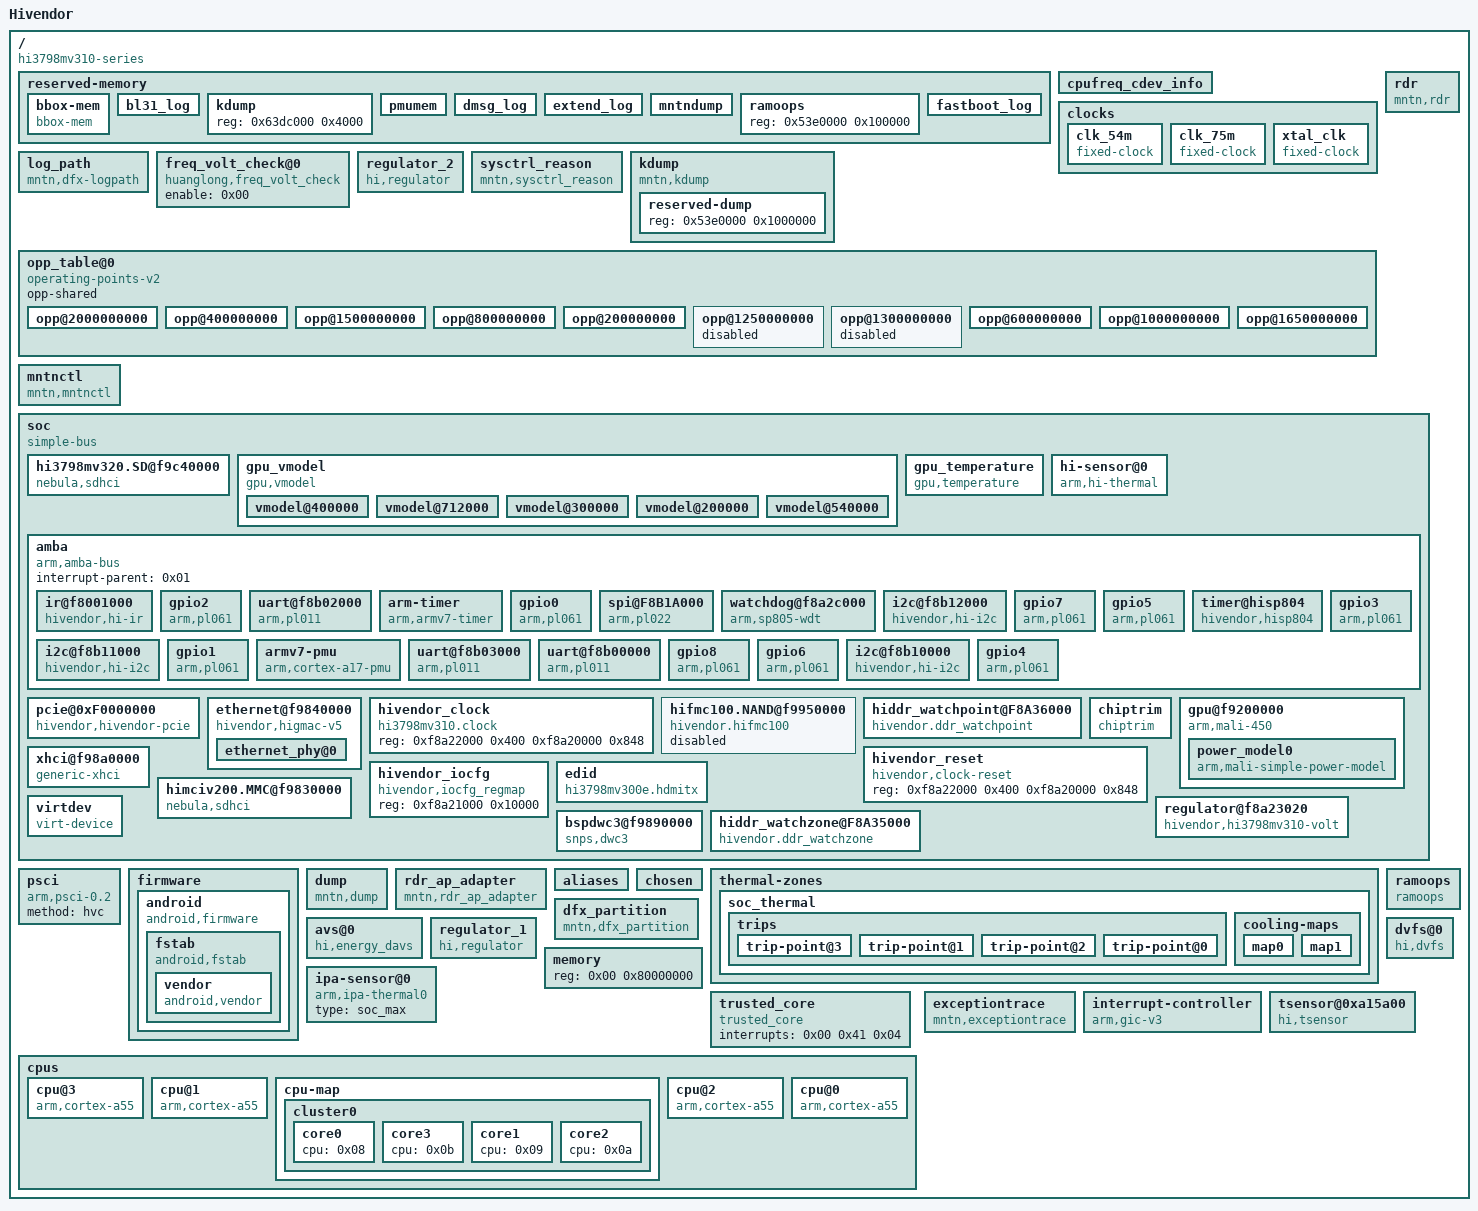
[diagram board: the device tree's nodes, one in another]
/dts-v1/;

/ {
	compatible = "hi3798mv310-series";
	model = "Hivendor";
	interrupt-parent = <0x01>;
	#address-cells = <0x01>;
	#size-cells = <0x01>;

	reserved-memory {
		ranges;
		#address-cells = <0x01>;
		#size-cells = <0x01>;
		phandle = <0x1f>;

		bbox-mem {
			compatible = "bbox-mem";
			no-map;
			phandle = <0x06>;
			reg = <0x5702000 0x4de000>;
		};

		bl31_log {
			no-map;
			reg = <0x5660000 0x80000>;
		};

		kdump {
			reg = <0x63dc000 0x4000>;
		};

		pmumem {
			no-map;
			reg = <0x5701000 0x1000>;
		};

		dmsg_log {
			no-map;
			reg = <0x54e0000 0x80000>;
		};

		extend_log {
			no-map;
			reg = <0x5560000 0x100000>;
		};

		mntndump {
			no-map;
			phandle = <0x07>;
			reg = <0x5700000 0x1000>;
		};

		ramoops {
			phandle = <0x20>;
			reg = <0x53e0000 0x100000>;
		};

		fastboot_log {
			no-map;
			reg = <0x56e0000 0x20000>;
		};
	};

	cpufreq_cdev_info {
		hi,cluster_num = <0x01>;
		hi,temperature_scale_capacitance = "-13169\03960\0-68\01\0605";
		hi,static_power_core_cap = "45\0-11969\01000";
		hi,hpm_param = <0xf80000b4 0x10 0xffff 0xe6 0x14a>;
		hi,ipa_cpufreq_table_index = <0x00>;
		hi,cluster_dyn_capacitance = <0x22f>;
		hi,cluster_static_capacitance = <0x8c>;
	};

	clocks {

		clk_54m {
			compatible = "fixed-clock";
			#clock-cells = <0x00>;
			phandle = <0x21>;
			clock-output-names = "clk54M";
			clock-frequency = <0x337f980>;
		};

		clk_75m {
			compatible = "fixed-clock";
			#clock-cells = <0x00>;
			phandle = <0x10>;
			clock-output-names = "clk75M";
			clock-frequency = <0x47868c0>;
		};

		xtal_clk {
			compatible = "fixed-clock";
			#clock-cells = <0x00>;
			phandle = <0x0f>;
			clock-output-names = "clk24M";
			clock-frequency = <0x16e3600>;
		};
	};

	log_path {
		compatible = "mntn,dfx-logpath";
		dfx_ready_path = "/data/lost+found";
		dfx_root_path = "/data/";
	};

	freq_volt_check@0 {
		compatible = "huanglong,freq_volt_check";
		enable = <0x00>;
		phandle = <0x1d>;
	};

	rdr {
		bbox_area_coreid = <0x01 0x02 0x04 0x08 0x10 0x20 0x40 0x80 0x100 0x200 0x400 0x800 0x1000 0x2000 0x4000 0x8000 0x10000>;
		rdr-dumpctl = "1111111111100000";
		compatible = "mntn,rdr";
		rdr-diaginfo-size = <0x20000>;
		bbox_area_names = "AP\0CP\0TEEOS\0HIFI\0BL31\0IOM3\0ISP\0IVP\0EMMC\0MODEMAP\0CLK\0REGULATOR\0BFM\0OUTSEE\0NPU\0CONN\0EXCEPTIONTRACE";
		rdr-log-max-nums = <0x0a>;
		rdr_area_sizes = <0x00 0x00 0x40000 0x40000 0x00 0x00 0x00 0x00 0x00 0x00 0x00 0x00 0x10000 0x00 0x00 0x2000 0x00>;
		rdr-log-max-size = <0x1f400000>;
		status = "ok";
		unexpected-max-reboot-times = <0x05>;
		bbox_addr = <0x06>;
		wait-dumplog-timeout = <0x1d4c0>;
		rdr_area_num = <0x11>;
	};

	regulator_2 {
		duty_step_value = <0x01>;
		compatible = "hi,regulator";
		pwm_addr = <0xf8a23018>;
		status = "okay";
		step_num = <0xdd>;
		phandle = <0x0e>;
		volt_reg_sleep_time = <0x00>;
		regulator-min-microvolt = <0xb90f0>;
		volt_reg_type = <0x00>;
		regulator-max-microvolt = <0x124f80>;
		regulator-always-on;
		volt_reg_step = <0x00>;
		max_v_duty = <0x00>;
		regulator-name = "cpu";
	};

	sysctrl_reason {
		compatible = "mntn,sysctrl_reason";
		sysctrl_reason_offset = <0x00 0x01 0x02 0x03 0x04 0x05 0x06 0x07 0x08 0x09 0x0a 0x0b 0x0c 0x0d 0x0e 0x0f 0x10 0x11 0x12 0x13 0x14 0x15 0x16 0x17>;
		sysctrl_reason_string = "AP_S_TSENSOR0\0AP_S_TSENSOR1\0G3D_S_G3DTSENSOR\0softreset\0AP_S_AWDT\0CHARGER_S_WDT\0LPM3_S_LPMCURST\0CP_S_CPTSENSOR\0IOM3_S_IOMCURST\0ASP_S_ASPWD\0CP_S_CPWD\0CP_S_CPWD\0IVP_S_IVPWD\0ISP_S_ISPWD\0AP_S_DDR_SELFREFLASH\0AP_S_DDR_FATAL_INTER\0AP_S_DDR_FATAL_INTER\0AP_S_DDR_FATAL_INTER\0AP_S_DDR_FATAL_INTER\0AP_S_DDR_UCE_WD\0AP_S_DDR_UCE_WD\0AP_S_DDR_UCE_WD\0AP_S_DDR_UCE_WD\0OCBC_S_WD";
	};

	kdump {
		compatible = "mntn,kdump";

		reserved-dump {
			#address-cells = <0x01>;
			#size-cells = <0x01>;
			reg = <0x53e0000 0x1000000>;
		};
	};

	opp_table@0 {
		compatible = "operating-points-v2";
		phandle = <0x0d>;
		opp-shared;

		opp@2000000000 {
			opp-microvolt = <0xf4240>;
			opp-hz = <0x00 0x77359400>;
			opp-microamp = <0xafc8>;
			clock-latency-ns = <0x493e0>;
		};

		opp@400000000 {
			opp-microvolt = <0xf4240>;
			opp-hz = <0x00 0x17d78400>;
			opp-microamp = <0x2710>;
			clock-latency-ns = <0x493e0>;
		};

		opp@1500000000 {
			opp-microvolt = <0xf4240>;
			opp-hz = <0x00 0x59682f00>;
			opp-microamp = <0xafc8>;
			clock-latency-ns = <0x493e0>;
		};

		opp@800000000 {
			opp-microvolt = <0xf4240>;
			opp-hz = <0x00 0x2faf0800>;
			opp-microamp = <0x2ee0>;
			clock-latency-ns = <0x493e0>;
		};

		opp@200000000 {
			opp-microvolt = <0xf4240>;
			opp-hz = <0x00 0xbebc200>;
			opp-microamp = <0x2710>;
			clock-latency-ns = <0x493e0>;
		};

		opp@1250000000 {
			opp-microvolt = <0xf4240>;
			opp-hz = <0x00 0x4a817c80>;
			opp-microamp = <0xafc8>;
			clock-latency-ns = <0x493e0>;
			status = "disabled";
		};

		opp@1300000000 {
			opp-microvolt = <0xf4240>;
			opp-hz = <0x00 0x4d7c6d00>;
			opp-microamp = <0xafc8>;
			clock-latency-ns = <0x493e0>;
			status = "disabled";
		};

		opp@600000000 {
			opp-microvolt = <0xf4240>;
			opp-hz = <0x00 0x23c34600>;
			opp-microamp = <0x2ee0>;
			clock-latency-ns = <0x493e0>;
		};

		opp@1000000000 {
			opp-microvolt = <0xf4240>;
			opp-hz = <0x00 0x3b9aca00>;
			opp-microamp = <0x2ee0>;
			clock-latency-ns = <0x493e0>;
		};

		opp@1650000000 {
			opp-microvolt = <0xf4240>;
			opp-hz = <0x00 0x62590080>;
			opp-microamp = <0xafc8>;
			clock-latency-ns = <0x493e0>;
		};
	};

	__symbols__ {
		tsensor = "/tsensor@0xa15a00";
		gpio2 = "/soc/amba/gpio2";
		gpu_vmodel = "/soc/gpu_vmodel";
		vddgpu = "/soc/regulator@f8a23020";
		bspdwc3 = "/soc/bspdwc3@f9890000";
		ir = "/soc/amba/ir@f8001000";
		gpio0 = "/soc/amba/gpio0";
		gpu_temperature = "/soc/gpu_temperature";
		gpu = "/soc/gpu@f9200000";
		regulator_2 = "/regulator_2";
		rsvmem = "/reserved-memory";
		clk_54m = "/clocks/clk_54m";
		cpu_opp_table = "/opp_table@0";
		gpio7 = "/soc/amba/gpio7";
		watchdog0 = "/soc/amba/watchdog@f8a2c000";
		hii2c2 = "/soc/amba/i2c@f8b12000";
		freq_volt_check = "/freq_volt_check@0";
		gic = "/interrupt-controller";
		gpio5 = "/soc/amba/gpio5";
		hivendor_clock = "/soc/hivendor_clock";
		threshold = "/thermal-zones/soc_thermal/trips/trip-point@0";
		uart2 = "/soc/amba/uart@f8b02000";
		hii2c0 = "/soc/amba/i2c@f8b10000";
		avs_compensation = "/avs@0";
		CPU2 = "/cpus/cpu@2";
		hiddr_watchzone = "/soc/hiddr_watchzone@F8A35000";
		emmc = "/soc/himciv200.MMC@f9830000";
		spi = "/soc/amba/spi@F8B1A000";
		gpio3 = "/soc/amba/gpio3";
		pcie = "/soc/pcie@0xF0000000";
		uart0 = "/soc/amba/uart@f8b00000";
		CPU0 = "/cpus/cpu@0";
		fmc = "/soc/hifmc100.NAND@f9950000";
		hdmitx = "/soc/edid";
		chiptrim = "/soc/chiptrim";
		gpio1 = "/soc/amba/gpio1";
		clk_75m = "/clocks/clk_75m";
		higmac0 = "/soc/ethernet@f9840000";
		critical = "/thermal-zones/soc_thermal/trips/trip-point@3";
		mntn_mem = "/reserved-memory/bbox-mem";
		xtal_clk = "/clocks/xtal_clk";
		hivendor_reset = "/soc/hivendor_reset";
		hivendor_iocfg = "/soc/hivendor_iocfg";
		cluster0 = "/cpus/cpu-map/cluster0";
		dvfs = "/dvfs@0";
		sdio = "/soc/hi3798mv320.SD@f9c40000";
		regulator_1 = "/regulator_1";
		power_model0 = "/soc/gpu@f9200000/power_model0";
		gpio8 = "/soc/amba/gpio8";
		hi_sensor0 = "/soc/hi-sensor@0";
		xhci_1 = "/soc/xhci@f98a0000";
		ramoops_ram = "/reserved-memory/ramoops";
		ipa_sensor0 = "/ipa-sensor@0";
		gpio6 = "/soc/amba/gpio6";
		dump_mem = "/reserved-memory/mntndump";
		uart3 = "/soc/amba/uart@f8b03000";
		hii2c1 = "/soc/amba/i2c@f8b11000";
		hiddr_watchpoint = "/soc/hiddr_watchpoint@F8A36000";
		CPU3 = "/cpus/cpu@3";
		gpio4 = "/soc/amba/gpio4";
		eth_phy0 = "/soc/ethernet@f9840000/ethernet_phy@0";
		target = "/thermal-zones/soc_thermal/trips/trip-point@1";
		hot = "/thermal-zones/soc_thermal/trips/trip-point@2";
		CPU1 = "/cpus/cpu@1";
	};

	mntnctl {
		compatible = "mntn,mntnctl";
		mntnctl = "010010111100101010111111101001100000011000001";
	};

	soc {
		compatible = "simple-bus";
		device_type = "soc";
		ranges = <0x00 0x00 0xffffffff>;
		#address-cells = <0x01>;
		#size-cells = <0x01>;

		hi3798mv320.SD@f9c40000 {
			sd-uhs-sdr25;
			compatible = "nebula,sdhci";
			clocks = <0x0c 0x2a4>;
			devid = <0x01>;
			cap-sd-highspeed;
			resets = <0x11 0x2a4 0x10 0x11 0x2a4 0x11 0x11 0x2a4 0x12 0x11 0x2a8 0x01>;
			clock-names = "mmc_clk";
			status = "okay";
			interrupts = <0x00 0x56 0x04>;
			bus-width = <0x04>;
			phandle = <0x37>;
			sd-uhs-sdr50;
			sd-uhs-sdr12;
			reg = <0xf9c40000 0x1000>;
			sd-uhs-sdr104;
			iocfg_regmap = <0x13>;
			reset-names = "crg_reset\0crg_tx\0crg_rx\0dll_reset";
			crg_regmap = <0x0c>;
			max-frequency = <0xb71b000>;
		};

		gpu_vmodel {
			compatible = "gpu,vmodel";
			phandle = <0x16>;

			vmodel@400000 {
				vmodel-hgain = <0x00>;
				vmodel-constant = <0x494>;
				vmodel-lgain = <0x32>;
				vmodel-minimum = <0x32a>;
				vmodel-ratio = <0x4c9>;
				vmodel-otp-volt = <0x28>;
			};

			vmodel@712000 {
				vmodel-hgain = <0x00>;
				vmodel-constant = <0x553>;
				vmodel-lgain = <0x1e>;
				vmodel-minimum = <0x32a>;
				vmodel-ratio = <0x677>;
				vmodel-otp-volt = <0x28>;
			};

			vmodel@300000 {
				vmodel-hgain = <0x00>;
				vmodel-constant = <0x479>;
				vmodel-lgain = <0x28>;
				vmodel-minimum = <0x32a>;
				vmodel-ratio = <0x480>;
				vmodel-otp-volt = <0x28>;
			};

			vmodel@200000 {
				vmodel-hgain = <0x00>;
				vmodel-constant = <0x479>;
				vmodel-lgain = <0x28>;
				vmodel-minimum = <0x32a>;
				vmodel-ratio = <0x480>;
				vmodel-otp-volt = <0x28>;
			};

			vmodel@540000 {
				vmodel-hgain = <0x00>;
				vmodel-constant = <0x494>;
				vmodel-lgain = <0x32>;
				vmodel-minimum = <0x32a>;
				vmodel-ratio = <0x4c9>;
				vmodel-otp-volt = <0x28>;
			};
		};

		gpu_temperature {
			h_temperature_h = <0x2d>;
			compatible = "gpu,temperature";
			phandle = <0x17>;
			l_temperature_l = <0x23>;
			h_temperature_l = <0x28>;
			l_temperature_h = <0x28>;
		};

		hi-sensor@0 {
			compatible = "arm,hi-thermal";
			#thermal-sensor-cells = <0x01>;
			phandle = <0x23>;
		};

		amba {
			compatible = "arm,amba-bus";
			ranges;
			interrupt-parent = <0x01>;
			#address-cells = <0x01>;
			#size-cells = <0x01>;

			ir@f8001000 {
				compatible = "hivendor,hi-ir";
				clocks = <0x0c 0x384>;
				interrupts = <0x00 0x2f 0x04>;
				phandle = <0x31>;
				reg = <0xf8001000 0x1000>;
				linux,rc-map-name = "rc-hi";
			};

			gpio2 {
				compatible = "arm,pl061\0arm,primecell";
				clocks = <0x0f>;
				clock-names = "apb_pclk";
				gpio-controller;
				#interrupt-cells = <0x02>;
				interrupts = <0x00 0x6e 0x04>;
				phandle = <0x26>;
				arm,primecell-periphid = <0x41061>;
				reg = <0xf8b22000 0x1000>;
				#gpio-cells = <0x02>;
				interrupt-controller;
			};

			uart@f8b02000 {
				compatible = "arm,pl011\0arm,primecell";
				clocks = <0x10>;
				clock-names = "apb_pclk";
				status = "okay";
				interrupts = <0x00 0x33 0x04>;
				phandle = <0x33>;
				arm,primecell-periphid = <0x241011>;
				reg = <0xf8b02000 0x1000>;
			};

			arm-timer {
				compatible = "arm,armv7-timer";
				interrupts = <0x01 0x0d 0xf04 0x01 0x0e 0xf04>;
				clock-frequency = <0x16e3600>;
			};

			gpio0 {
				compatible = "arm,pl061\0arm,primecell";
				clocks = <0x0f>;
				clock-names = "apb_pclk";
				gpio-controller;
				#interrupt-cells = <0x02>;
				interrupts = <0x00 0x6c 0x04>;
				phandle = <0x24>;
				arm,primecell-periphid = <0x41061>;
				reg = <0xf8b20000 0x1000>;
				#gpio-cells = <0x02>;
				interrupt-controller;
			};

			spi@F8B1A000 {
				compatible = "arm,pl022\0arm,primecell";
				clocks = <0x0c 0x70>;
				clock-names = "apb_pclk";
				#address-cells = <0x01>;
				interrupts = <0x00 0x2d 0x04>;
				#size-cells = <0x00>;
				phandle = <0x30>;
				arm,primecell-periphid = <0x41022>;
				reg = <0xf8b1a000 0x1000>;
				num-cs = <0x02>;
				pl022,rt;
			};

			watchdog@f8a2c000 {
				start_ping_in_kernel = <0x01>;
				compatible = "arm,sp805-wdt\0arm,primecell";
				clocks = <0x0f>;
				clock-names = "apb_pclk";
				interrupts = <0x00 0x1d 0x04>;
				phandle = <0x2c>;
				arm,primecell-periphid = <0x141805>;
				reg = <0xf8a2c000 0x1000>;
				timeout-sec = <0x0a>;
			};

			i2c@f8b12000 {
				compatible = "hivendor,hi-i2c";
				clocks = <0x0c 0x1b4>;
				clock-names = "apb_pclk";
				#address-cells = <0x01>;
				interrupts = <0x00 0x28 0x04>;
				#size-cells = <0x00>;
				phandle = <0x2f>;
				reg = <0xf8b12000 0x1000>;
				clock-frequency = <0x61a80>;
			};

			gpio7 {
				compatible = "arm,pl061\0arm,primecell";
				clocks = <0x0f>;
				clock-names = "apb_pclk";
				gpio-controller;
				#interrupt-cells = <0x02>;
				interrupts = <0x00 0x73 0x04>;
				phandle = <0x2a>;
				arm,primecell-periphid = <0x41061>;
				reg = <0xf8b27000 0x1000>;
				#gpio-cells = <0x02>;
				interrupt-controller;
			};

			gpio5 {
				compatible = "arm,pl061\0arm,primecell";
				clocks = <0x0f>;
				clock-names = "apb_pclk";
				gpio-controller;
				#interrupt-cells = <0x02>;
				interrupts = <0x00 0x71 0x00>;
				phandle = <0x28>;
				arm,primecell-periphid = <0x41061>;
				reg = <0xf8004000 0x1000>;
				#gpio-cells = <0x02>;
				interrupt-controller;
			};

			timer@hisp804 {
				compatible = "hivendor,hisp804";
				clocks = <0x0f>;
				clock-names = "apb_pclk";
				interrupts = <0x00 0x1a 0x04 0x00 0x3b 0x04 0x00 0x1b 0x04 0x00 0x3c 0x04>;
				reg = <0xf8a29000 0x20 0xf8a2a000 0x20 0xf8a2a020 0x20 0xf8a2b000 0x20 0xf8a2b020 0x20>;
			};

			gpio3 {
				compatible = "arm,pl061\0arm,primecell";
				clocks = <0x0f>;
				clock-names = "apb_pclk";
				gpio-controller;
				#interrupt-cells = <0x02>;
				interrupts = <0x00 0x6f 0x04>;
				phandle = <0x27>;
				arm,primecell-periphid = <0x41061>;
				reg = <0xf8b23000 0x1000>;
				#gpio-cells = <0x02>;
				interrupt-controller;
			};

			i2c@f8b11000 {
				compatible = "hivendor,hi-i2c";
				clocks = <0x0c 0x1b0>;
				clock-names = "apb_pclk";
				#address-cells = <0x01>;
				interrupts = <0x00 0x27 0x04>;
				#size-cells = <0x00>;
				phandle = <0x2e>;
				reg = <0xf8b11000 0x1000>;
				clock-frequency = <0x61a80>;
			};

			gpio1 {
				compatible = "arm,pl061\0arm,primecell";
				clocks = <0x0f>;
				clock-names = "apb_pclk";
				gpio-controller;
				#interrupt-cells = <0x02>;
				interrupts = <0x00 0x6d 0x04>;
				phandle = <0x25>;
				arm,primecell-periphid = <0x41061>;
				reg = <0xf8b21000 0x1000>;
				#gpio-cells = <0x02>;
				interrupt-controller;
			};

			armv7-pmu {
				compatible = "arm,cortex-a17-pmu";
				interrupts = <0x00 0x08 0x04 0x00 0x09 0x04 0x00 0x0a 0x04 0x00 0x0b 0x04>;
			};

			uart@f8b03000 {
				compatible = "arm,pl011\0arm,primecell";
				clocks = <0x10>;
				clock-names = "apb_pclk";
				status = "okay";
				interrupts = <0x00 0x34 0x04>;
				phandle = <0x34>;
				arm,primecell-periphid = <0x241011>;
				reg = <0xf8b03000 0x1000>;
			};

			uart@f8b00000 {
				compatible = "arm,pl011\0arm,primecell";
				clocks = <0x10>;
				clock-names = "apb_pclk";
				status = "okay";
				interrupts = <0x00 0x31 0x04>;
				phandle = <0x32>;
				arm,primecell-periphid = <0x241011>;
				reg = <0xf8b00000 0x1000>;
			};

			gpio8 {
				compatible = "arm,pl061\0arm,primecell";
				clocks = <0x0f>;
				clock-names = "apb_pclk";
				gpio-controller;
				#interrupt-cells = <0x02>;
				interrupts = <0x00 0x74 0x04>;
				phandle = <0x2b>;
				arm,primecell-periphid = <0x41061>;
				reg = <0xf8b28000 0x1000>;
				#gpio-cells = <0x02>;
				interrupt-controller;
			};

			gpio6 {
				compatible = "arm,pl061\0arm,primecell";
				clocks = <0x0f>;
				clock-names = "apb_pclk";
				gpio-controller;
				#interrupt-cells = <0x02>;
				interrupts = <0x00 0x72 0x04>;
				phandle = <0x29>;
				arm,primecell-periphid = <0x41061>;
				reg = <0xf8b26000 0x1000>;
				#gpio-cells = <0x02>;
				interrupt-controller;
			};

			i2c@f8b10000 {
				compatible = "hivendor,hi-i2c";
				clocks = <0x0c 0x1ac>;
				clock-names = "apb_pclk";
				#address-cells = <0x01>;
				interrupts = <0x00 0x26 0x04>;
				#size-cells = <0x00>;
				phandle = <0x2d>;
				reg = <0xf8b10000 0x1000>;
				clock-frequency = <0x61a80>;
			};

			gpio4 {
				compatible = "arm,pl061\0arm,primecell";
				clocks = <0x0f>;
				clock-names = "apb_pclk";
				gpio-controller;
				#interrupt-cells = <0x02>;
				interrupts = <0x00 0x70 0x04>;
				phandle = <0x14>;
				arm,primecell-periphid = <0x41061>;
				reg = <0xf8b24000 0x1000>;
				#gpio-cells = <0x02>;
				interrupt-controller;
			};
		};

		pcie@0xF0000000 {
			reset-gpio = <0x14 0x01 0x01>;
			compatible = "hivendor,hivendor-pcie\0snps,dw-pcie";
			clocks = <0x0c 0x3a0>;
			device_type = "pci";
			num-lanes = <0x01>;
			clock-names = "pcie_clk";
			ranges = <0x800 0x00 0xf2100000 0xf2100000 0x00 0x20000 0x81000000 0x00 0x00 0xf4000000 0x00 0x10000 0x82000000 0x00 0xf3000000 0xf3000000 0x00 0x1000000>;
			num-viewport = <0x03>;
			status = "okay";
			#address-cells = <0x03>;
			interrupts = <0x00 0x83 0x04 0x00 0x91 0x04 0x00 0x92 0x04 0x00 0x80 0x04>;
			#size-cells = <0x02>;
			phandle = <0x3b>;
			speed-limit = <0x02>;
			reg = <0xf0001000 0x200 0xf0000000 0x1000 0xf8c5f000 0x200>;
			#gpio-cells = <0x02>;
			interrupt-names = "intx\0protect-read-int\0protect-write-int\0msi";
		};

		ethernet@f9840000 {
			internal-phy;
			phy-handle = <0x12>;
			compatible = "hivendor,higmac-v5";
			mac-address = [14 2e 43 08 0f 15];
			clocks = <0x0c 0x3bc 0x0c 0xd0>;
			resets = <0x11 0x3bc 0x00 0x11 0xd0 0x00 0x11 0xcc 0x05>;
			phy-gpio-bit = <0x06>;
			clock-names = "higmac_clk\0macif_clk";
			phy-gpio-base = <0xf8b22000>;
			status = "okay";
			#address-cells = <0x01>;
			interrupts = <0x00 0x50 0x04 0x00 0x51 0x04 0x00 0x53 0x04 0x00 0x55 0x04>;
			#size-cells = <0x00>;
			phandle = <0x35>;
			reg = <0xf9840000 0x1000 0xf984300c 0x04>;
			phy-mode = "mii";
			reset-names = "port_reset\0macif_reset\0phy_reset";

			ethernet_phy@0 {
				phy_fixup_id = <0x1cc878>;
				phandle = <0x12>;
				reg = <0x03>;
				phy_fixup0 = <0x1f0d08 0x00 0x110100 0x02 0x1f0000 0x00>;
			};
		};

		hivendor_clock {
			compatible = "hi3798mv310.clock\0syscon";
			#clock-cells = <0x01>;
			phandle = <0x0c>;
			reg = <0xf8a22000 0x400 0xf8a20000 0x848>;
		};

		hifmc100.NAND@f9950000 {
			compatible = "hivendor.hifmc100";
			clocks = <0x0c 0x380>;
			clock-names = "clk";
			status = "disabled";
			interrupts = <0x00 0x36 0x04>;
			phandle = <0x38>;
			reg = <0xf9950000 0x100 0xfe200000 0x2176>;
		};

		hiddr_watchpoint@F8A36000 {
			compatible = "hivendor.ddr_watchpoint";
			interrupts = <0x00 0x1f 0x04>;
			phandle = <0x3c>;
			reg = <0xf8a36000 0x1000>;
		};

		chiptrim {
			compatible = "chiptrim";
			chiptrim2 = <0x21>;
			chiptrim0 = <0x21fb9420>;
			phandle = <0x22>;
			chiptrim1 = <0x34623>;
		};

		gpu@f9200000 {
			gpu_vmodel = <0x16>;
			cooling-min-state = <0x00>;
			pmu_domain_config = <0x01 0x02 0x02 0x00 0x00 0x00 0x00 0x00 0x00 0x01 0x02 0x00>;
			compatible = "arm,mali-450\0arm,mali-utgard";
			clocks = <0x0c 0x124>;
			gpu_temperature = <0x17>;
			operating-points-tt = <0xbebc200 0x30d40 0x11e1a300 0x493e0 0x17d78400 0x61a80 0x202fbf00 0x83d60 0x2a704200 0xadd40>;
			min-utilization = <0x1e>;
			default-frequency = <0x202fbf00>;
			clock-names = "clk_mali";
			ipa-model = "mali-simple-power-model";
			status = "okay";
			interrupt-parent = <0x01>;
			interrupts = <0x00 0x5e 0x04 0x00 0x5e 0x04 0x00 0x5e 0x04 0x00 0x5e 0x04 0x00 0x5e 0x04 0x00 0x5e 0x04 0x00 0x5e 0x04 0x00 0x5e 0x04>;
			irq_affinity = <0x03>;
			phandle = <0x05>;
			mali-supply = <0x15>;
			reg = <0xf9200000 0x10000>;
			cooling-max-state = <0x06>;
			max-utilization = <0x3c>;
			#cooling-cells = <0x02>;
			min-frequency = <0xbebc200>;
			interrupt-names = "IRQGP\0IRQGPMMU\0IRQPP0\0IRQPPMMU0\0IRQPP1\0IRQPPMMU1\0IRQPMU\0IRQPP";
			max-frequency = "*pB";
			pmu_switch_delay = <0x1ff>;

			power_model0 {
				dynamic-coefficient = <0x299>;
				compatible = "arm,mali-simple-power-model";
				static-coefficient = <0x9d05>;
				thermal-zone = [00];
				phandle = <0x40>;
				ts = <0xffffac8e 0xf01 0xffffffa6 0x01>;
			};
		};

		hivendor_reset {
			compatible = "hivendor,clock-reset\0syscon";
			#reset-cells = <0x02>;
			phandle = <0x11>;
			reg = <0xf8a22000 0x400 0xf8a20000 0x848>;
		};

		hivendor_iocfg {
			compatible = "hivendor,iocfg_regmap\0syscon";
			#reset-cells = <0x03>;
			phandle = <0x13>;
			reg = <0xf8a21000 0x10000>;
		};

		xhci@f98a0000 {
			compatible = "generic-xhci";
			clocks = <0x0c 0x2d0>;
			clock-names = "clk";
			status = "okay";
			interrupts = <0x00 0x40 0x04>;
			phandle = <0x3a>;
			reg = <0xf98a0000 0x10000>;
			usb2-lpm-disable;
		};

		edid {
			compatible = "hi3798mv300e.hdmitx";
			under594m-y420 = <0x00>;
			phandle = <0x3f>;
			hdmimode-onlyvsdb = <0x00>;
		};

		himciv200.MMC@f9830000 {
			cap-mmc-highspeed;
			cap-mmc-hw-reset;
			compatible = "nebula,sdhci";
			clocks = <0x0c 0x288>;
			devid = <0x00>;
			resets = <0x11 0x288 0x10 0x11 0x288 0x11 0x11 0x288 0x12 0x11 0x28c 0x01>;
			clock-names = "mmc_clk";
			status = "okay";
			interrupts = <0x00 0x23 0x04>;
			bus-width = <0x08>;
			mmc-hs400-1_8v;
			phandle = <0x36>;
			mmc-hs400-enhanced-strobe;
			reg = <0xf9830000 0x1000>;
			iocfg_regmap = <0x13>;
			reset-names = "crg_reset\0crg_tx\0crg_rx\0dll_reset";
			crg_regmap = <0x0c>;
			non-removable;
			max-frequency = <0xb71b000>;
			mmc-hs200-1_8v;
		};

		regulator@f8a23020 {
			compatible = "hivendor,hi3798mv310-volt";
			reg-names = "Hivendor GPU Regulator";
			status = "okay";
			phandle = <0x3e>;
			regulator-min-microvolt = <0xafc80>;
			reg = <0xf8a2301c 0x04>;
			regulator-max-microvolt = <0x1214e8>;
			regulator-always-on;
			regulator-name = "vdd-gpu";
		};

		bspdwc3@f9890000 {
			compatible = "snps,dwc3";
			clocks = <0x0c 0xb8>;
			clock-names = "clk";
			snps,usb2-lpm-disable;
			status = "okay";
			interrupts = <0x00 0x3f 0x04>;
			phandle = <0x39>;
			reg = <0xf9890000 0x10000>;
			dr_mode = "otg";
			interrupt-names = "peripheral";
			maximum-speed = "high-speed";
		};

		hiddr_watchzone@F8A35000 {
			compatible = "hivendor.ddr_watchzone";
			interrupts = <0x00 0x1f 0x04>;
			phandle = <0x3d>;
			reg = <0xf8a35000 0x1000>;
		};

		virtdev {
			compatible = "virt-device";
			interrupts = <0x00 0x1d 0x04 0x00 0x24 0x04 0x00 0x25 0x04 0x00 0x2f 0x04 0x00 0x2f 0x04 0x00 0x30 0x04 0x00 0x30 0x04 0x00 0x47 0x04 0x00 0x4b 0x04 0x00 0x52 0x04 0x00 0x54 0x04 0x00 0x58 0x04 0x00 0x5a 0x04 0x00 0x5b 0x04 0x00 0x5b 0x04 0x00 0x5d 0x04 0x00 0x5e 0x04 0x00 0x5f 0x04 0x00 0x5f 0x04 0x00 0x60 0x04 0x00 0x61 0x04 0x00 0x65 0x04 0x00 0x66 0x04 0x00 0x68 0x04 0x00 0x69 0x04 0x00 0x6a 0x04 0x00 0x7e 0x04 0x00 0x88 0x04 0x00 0x89 0x04 0x00 0x8a 0x04 0x00 0x8b 0x04 0x00 0x92 0x04 0x00 0x93 0x04 0x00 0x94 0x04 0x00 0x94 0x04 0x00 0x95 0x04 0x00 0x96 0x04 0x00 0x9d 0x04>;
			interrupt-names = "wdg0\0sci0\0sci1\0ir_std\0ir_s2\0keyled_ct1642\0keyled_std\0gsf0\0spacc_int_ree\0dmx\0aiao\0hdmi\0vdp\0tde\0gfx2d\0vpss0\0gpu\0vdec_vdh\0mdma_irq\0png\0jpeg\0venc\0jpge\0vdec_scd\0vdec_vdh_safe\0vdec_scd_safe\0spacc_int_tee\0vdh_pxp_safe\0vdh_pxp\0vdh_bd_safe\0vdh_bd\0SecInvokeirq\0hdmi_cec\0mmu_vdh_safe\0mmu_vdh_s\0mmu_vdh\0pastc\0sm2";
		};
	};

	psci {
		compatible = "arm,psci-0.2";
		method = "hvc";
	};

	firmware {

		android {
			compatible = "android,firmware";

			fstab {
				compatible = "android,fstab";

				vendor {
					compatible = "android,vendor";
					dev = "/dev/block/platform/soc/f9830000.himciv200.MMC/by-name/vendor";
					type = "ext4";
					fsmgr_flags = "wait";
					mnt_flags = "ro,barrier=1,inode_readahead_blks=8";
				};
			};
		};
	};

	dump {
		compatible = "mntn,dump";
		dump_area_sizes = <0x200 0x30 0x10 0x800 0x100 0x30 0x30 0x20 0x40 0x100>;
		dump_addr = <0x07>;
		status = "ok";
	};

	rdr_ap_adapter {
		reg-dump-regions = <0x03>;
		ap_dump_mem_modu_tmc_size = <0x00>;
		compatible = "mntn,rdr_ap_adapter";
		ap_dump_mem_modu_noc_size = <0x00>;
		ap_trace_tasklet_size = <0x2000>;
		ldrx2dbg-abs-timer = <0xfa89b000 0x1000 0x534 0x538>;
		ap_trace_mem_alloc_size = <0x80000>;
		reg-names = "sctrl\0pctrl\0peri_crg";
		ap_trace_task_size = <0x80000>;
		ap_trace_diaginfo_size = <0x10000>;
		ap_trace_worker_size = <0x4000>;
		ap_trace_irq_size = <0x80000>;
		ap_dump_mem_modu_gap_size = <0x00>;
		status = "ok";
		ap_trace_hung_task_size = <0x1000>;
		#address-cells = <0x02>;
		ap_trace_cpu_on_off_size = <0x00>;
		#size-cells = <0x02>;
		ap_trace_ion_alloc_size = <0x80000>;
		ap_trace_syscall_size = <0x00>;
		ap_dump_mem_modu_ddr_size = <0x00>;
		ap_last_task_switch = <0x01>;
		reg = <0x00 0xfa89b000 0x00 0x800 0x00 0xfe02e000 0x00 0xc00 0x00 0xfff05000 0x00 0xc00>;
		ap_trace_time_size = <0x40000>;
		ap_trace_cpu_idle_size = <0x00>;
		ap_dump_mem_modu_mntn_fac_size = <0x00>;
	};

	aliases {
		i2c1 = "/soc/amba/i2c@f8b11000";
		dwc30 = "/soc/bspdwc3@f9890000";
		spi0 = "/soc/amba/spi@F8B1A000";
		net_phy_addr0 = "/soc/ethernet@f9840000/ethernet_phy@0";
		uart2 = "/soc/amba/uart@f8b02000";
		emmc = "/soc/himciv200.MMC@f9830000";
		pcie = "/soc/pcie@0xF0000000";
		uart0 = "/soc/amba/uart@f8b00000";
		i2c2 = "/soc/amba/i2c@f8b12000";
		fmc = "/soc/hifmc100.NAND@f9950000";
		chiptrim = "/soc/chiptrim";
		i2c0 = "/soc/amba/i2c@f8b10000";
		sdio = "/soc/hi3798mv320.SD@f9c40000";
		net_phy0 = "/soc/ethernet@f9840000";
		uart3 = "/soc/amba/uart@f8b03000";
		xhci1 = "/soc/xhci@f98a0000";
	};

	chosen {
		bootargs = "androidboot.hardware=bigfish androidboot.selinux=permissive androidboot.serialno=00411300202818002605142E43080F15 console=ttyAMA0,115200 blkdevparts=mmcblk0:2M(fastboot),512K(bootargs),512K(bootargsbak),19M(recovery),2M(deviceinfo),8M(securestore),2M(atf),8M(baseparam),8M(pqparam),2M(dtbo),10M(logo),10M(logobak),20M(dfx),20M(recoverybak),60M(boot),20M(misc),20M(trustedcore),1200M(system)ro,800M(cache),400M(vendor)ro,800M(backup),50M(private),256M(cmcc),-(userdata) hbcomp=/dev/block/mmcblk0p18 init=/init root=/dev/mmcblk0p18 androidboot.dtbo_idx=0 pq=noacmuhd quiet nofmc nosd disp_offset_vfs=disable rootwait hhee_enable=1 mntnctl=010010111100101010111111101001100000011000001 last_bootup_keypoint=97 reboot_reason=AP_S_PANIC exception_subtype=SUB_APPANIC_SOFTLOCKUP mem=2G mmz=ddr,0,0,52M vmalloc=500M";
	};

	thermal-zones {

		soc_thermal {
			thermal-sensors = <0x02 0xff>;
			governor_name = "power_allocator";
			polling-delay = <0xc8>;
			polling-delay-passive = <0x32>;
			integral_cutoff = <0x00>;
			k_po = <0x7a>;
			sustainable-power = <0x708>;
			k_i = <0x0a>;
			k_pu = <0xf5>;

			trips {

				trip-point@3 {
					hysteresis = <0x3e8>;
					temperature = <0x1d4c0>;
					type = "critical";
					phandle = <0x1b>;
				};

				trip-point@1 {
					hysteresis = <0x3e8>;
					temperature = <0x1c138>;
					type = "passive";
					phandle = <0x03>;
				};

				trip-point@2 {
					hysteresis = <0x3e8>;
					temperature = <0x1ccf0>;
					type = "hot";
					phandle = <0x1a>;
				};

				trip-point@0 {
					hysteresis = <0x3e8>;
					temperature = <0x186a0>;
					type = "passive";
					phandle = <0x19>;
				};
			};

			cooling-maps {

				map0 {
					trip = <0x03>;
					contribution = <0x400>;
					cooling-device = <0x04 0xffffffff 0xffffffff>;
				};

				map1 {
					trip = <0x03>;
					contribution = <0x400>;
					cooling-device = <0x05 0xffffffff 0xffffffff>;
				};
			};
		};
	};

	dfx_partition {
		compatible = "mntn,dfx_partition";
		dfx_zerohung_size = <0x10000>;
		dfx_module_num = <0x02>;
		dfx_noreboot_size = <0x700000>;
	};

	avs@0 {
		compatible = "hi,energy_davs";
		tavs_vol_comp_2 = <0x00 0x00 0xfffffff6 0x00 0x00 0x14 0x1e 0x14 0x00 0x00>;
		tavs_enable = <0x01>;
		otp_comp_enable = <0x44f 0x00>;
		core_hpm_param = <0xf80000b4 0x00 0xffff 0x12c 0x1c2>;
		davs_enable = <0x01>;
		tavs_vol_comp_0 = <0x32 0x32 0x23 0x28 0x28 0x1e 0x1e 0x1e 0x00 0x28>;
		otp_comp_info = <0x44b 0x04 0x0f>;
		tavs_temp_node = <0x23 0x4b 0x64>;
		core_pavs_line_param = <0x06 0x0a 0x28>;
		core_vmin_param = <0x3d2 0x4bd 0x28 0x32a 0x41a 0x4b0>;
		hysteresis = <0x05>;
		tavs_vol_comp_3 = <0x00 0x00 0xfffffff6 0x00 0x00 0x14 0x1e 0x14 0x00 0x00>;
		pavs_enable = <0x00>;
		tavs_vol_comp_1 = <0x00 0x00 0x00 0x00 0x00 0x14 0x14 0x14 0x00 0x00>;
		phandle = <0x1e>;
		cpu_pavs_line_param = <0x06 0x0a 0x28>;
	};

	regulator_1 {
		duty_step_value = <0x01>;
		compatible = "hi,regulator";
		pwm_addr = <0xf8a2301c>;
		status = "okay";
		step_num = <0xdd>;
		phandle = <0x15>;
		volt_reg_sleep_time = <0x3e8>;
		regulator-min-microvolt = <0xb90f0>;
		volt_reg_type = <0x01>;
		regulator-max-microvolt = <0x124f80>;
		regulator-always-on;
		volt_reg_step = <0x1388>;
		max_v_duty = <0x00>;
		regulator-name = "dvdd";
	};

	memory {
		reg = <0x00 0x80000000>;
	};

	ipa-sensor@0 {
		compatible = "arm,ipa-thermal0";
		#thermal-sensor-cells = <0x01>;
		type = "soc_max";
		status = "ok";
		phandle = <0x02>;
	};

	ramoops {
		compatible = "ramoops";
		record-size = <0x40000>;
		event-size = <0x40000>;
		pmsg-size = <0x00>;
		ecc-size = <0x00>;
		console-size = <0x80000>;
		ftrace-size = <0x00>;
		reg = <0x53e0000 0x100000>;
		dump-oops = <0x01>;
	};

	trusted_core {
		compatible = "trusted_core";
		interrupts = <0x00 0x41 0x04>;
	};

	cpus {
		#address-cells = <0x01>;
		#size-cells = <0x00>;

		cpu@3 {
			compatible = "arm,cortex-a55";
			clocks = <0x0c 0x158>;
			device_type = "cpu";
			clock-names = "cpu_clk";
			enable-method = "psci";
			cpu-supply = <0x0e>;
			phandle = <0x0b>;
			operating-points-v2 = <0x0d>;
			reg = <0x300>;
		};

		cpu@1 {
			compatible = "arm,cortex-a55";
			clocks = <0x0c 0x158>;
			device_type = "cpu";
			clock-names = "cpu_clk";
			enable-method = "psci";
			cpu-supply = <0x0e>;
			phandle = <0x09>;
			operating-points-v2 = <0x0d>;
			reg = <0x100>;
		};

		cpu-map {

			cluster0 {
				phandle = <0x04>;
				#cooling-cells = <0x02>;

				core0 {
					cpu = <0x08>;
				};

				core3 {
					cpu = <0x0b>;
				};

				core1 {
					cpu = <0x09>;
				};

				core2 {
					cpu = <0x0a>;
				};
			};
		};

		cpu@2 {
			compatible = "arm,cortex-a55";
			clocks = <0x0c 0x158>;
			device_type = "cpu";
			clock-names = "cpu_clk";
			enable-method = "psci";
			cpu-supply = <0x0e>;
			phandle = <0x0a>;
			operating-points-v2 = <0x0d>;
			reg = <0x200>;
		};

		cpu@0 {
			compatible = "arm,cortex-a55";
			clocks = <0x0c 0x158>;
			device_type = "cpu";
			clock-names = "cpu_clk";
			enable-method = "psci";
			cpu-supply = <0x0e>;
			phandle = <0x08>;
			operating-points-v2 = <0x0d>;
			reg = <0x00>;
		};
	};

	exceptiontrace {
		compatible = "mntn,exceptiontrace";
		area_num = <0x01>;
		area_names = "AP";
		status = "ok";
		area_sizes = <0x200>;
	};

	dvfs@0 {
		cpu_freq_400000 = <0x505 0x432 0x37 0x32a 0x44c 0x4b0>;
		dvfs_quit_low_temp_comp_threshold = <0xff>;
		compatible = "hi,dvfs";
		otp_freq_800000 = <0x44d 0x00 0x0f>;
		dvfs_quit_high_temp_comp_threshold = <0xff>;
		cpu_freq_1250000 = <0x6d3 0x5eb 0x28 0x32a 0x44c 0x4b0>;
		cpu_freq_1000000 = <0x61c 0x563 0x28 0x32a 0x44c 0x4b0>;
		dvfs_enter_standby_threshold = <0x78>;
		cpu_freq_200000 = <0x505 0x432 0x37 0x32a 0x44c 0x4b0>;
		dvfs_enter_limiting_freq_threshold = <0xff>;
		otp_freq_600000 = <0x44c 0x04 0x0f>;
		otp_freq_1250000 = <0x44e 0x00 0x0f>;
		otp_freq_1000000 = <0x44d 0x04 0x0f>;
		cpu_freq_1500000 = <0x6d3 0x5eb 0x28 0x32a 0x44c 0x4b0>;
		otp_compensation_enable = <0x44f 0x01>;
		cpu_freq_800000 = <0x59a 0x4ea 0x28 0x32a 0x44c 0x4b0>;
		dvfs_quit_limiting_freq_threshold = <0xff>;
		dvfs_limit_max_freq = <0x16e360>;
		cpu_freq_2000000 = <0x00 0x47e 0x00 0x32a 0x47e 0x4b0>;
		dvfs_enter_high_temp_comp_threshold = <0xff>;
		cpu_freq_1650000 = <0x00 0x47e 0x00 0x32a 0x47e 0x4b0>;
		dvfs_quit_anti_aging_threshold = <0x5f>;
		phandle = <0x1c>;
		otp_freq_1500000 = <0x44e 0x00 0x0f>;
		otp_freq_400000 = <0x44c 0x00 0x0f>;
		cpu_freq_1300000 = <0x710 0x60e 0x28 0x32a 0x44c 0x4b0>;
		cpu_freq_600000 = <0x566 0x497 0x28 0x32a 0x44c 0x4b0>;
		core_regulator_name = "dvdd";
		dvfs_enter_anti_aging_threshold = <0x69>;
		hpm_param = <0xf80000b4 0x10 0xffff 0xb4 0x1ae>;
		dvfs_enter_low_temp_comp_threshold = <0xff>;
		dvfs_anti_aging_limit_freq = <0xf4240>;
		otp_freq_200000 = <0x44c 0x00 0x0f>;
	};

	interrupt-controller {
		compatible = "arm,gic-v3";
		#interrupt-cells = <0x03>;
		#address-cells = <0x00>;
		phandle = <0x01>;
		reg = <0xf1000000 0x10000 0xf1040000 0x80000>;
		interrupt-controller;
	};

	tsensor@0xa15a00 {
		hi,tsensor_ctrl_config = <0x72>;
		compatible = "hi,tsensor";
		hi,pmc_tsensorout_offset = <0x08>;
		hi,tsensor_trimming_otp_offset = <0x1db>;
		hi,tsensor_id = <0x00>;
		hi,tsensor_name = "cpu";
		hi,tsensor_reg_offset = <0x00>;
		hi,tsensor_trimming_otp_base = <0xf8ab0000>;
		hi,tsensor_trimming_otp_enable = <0x01>;
		phandle = <0x18>;
		hi,tsensor_reg = <0xf8a23028 0x1c>;
		hi,tsensor_scale_capacitance = <0x84 0xa5 0x328 0x28>;
		hi,sensors = <0x01>;
	};
};
